# coex_secure register map
Vendor: Texas Instruments
Peripheral module from a debugger description file (folder CC35X1E).
Registers are 32-bit, access per field, reset 0x0 unless marked. A register's access mark holds for its fields unless they carry their own. Offsets are as the file gives them; lines under a group give offsets from that group; [hi:lo] are bit positions; {n}, {i} and the like mark numbered series; 'fields as' and 'values as' point back to an identical list; <NAME> marks a mode.

## coex_secure
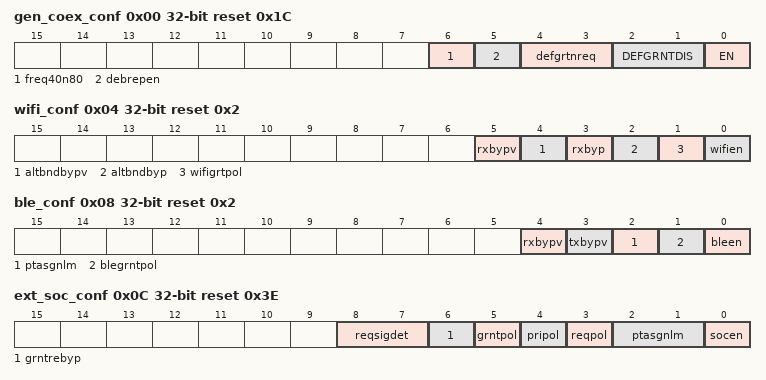
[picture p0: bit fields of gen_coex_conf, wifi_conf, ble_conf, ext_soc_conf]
0x00 gen_coex_conf reset 0x1C — General COEX Configurations. This register is a static configuration.
  [6] freq40n80 rw — This bit configuration is available to select the freq. at which COEX is operating. 1 --> 80 MHz; 0 --> 40 MHz.
  [5] debrepen rw — debug reporting enable: This bit configuration is available to enable or disable the debug reporting.0 --> No IRQ is generated; 1 --> Debug Mode enable. IRQ is generated whenever there is change in grant state.
  [4:3] defgrtnreq rw — def grant when no req: This bit configuration is available to select the entity which has the grant when there is no request from any entity.00 --> Wifi; 01 --> BLE, 10 --> SOC, 11 --> Wifi.
  [2:1] DEFGRNTDIS rw — def grant when coex disabled: This bit configuration is available to select the entity which has the grant when COEX is disabled. 00 --> Wifi; 01 --> BLE, 10 --> SOC, 11 --> invalid configuration.
  [0] EN rw — This bit configuration is available to enable or disable COEX. Enable --> 1; Disable --> 0.
0x04 wifi_conf reset 0x2 — Wifi Configuration. This register is available is to program Wifi related general configuration. This register is static configuration.
  [5] rxbypv rw — wifi rx only input bypass val: This bit configuration is available to bypass Wifi_RX_only value.
  [4] altbndbypv rw — wifi alt band input bypass val: This bit configuration is available to configure Wifi_alt_band value.
  [3] rxbyp rw — wifi rx only input bypass: This bit configuration is available to bypass Wifi RX only input. 1 --> Bypass wifi rx only input; 0 --> Do not bypass wifi rx only input.
  [2] altbndbyp rw — wifi alt band input bypass: This bit configuration is available to bypass Wifi alt band input. 1 --> Bypass wifi alt band input; 0 --> Do not bypass wifi alt band input.
  [1] wifigrtpol rw — This bit configuration is available to select Wifi Grant Polarity. 1 --> Default Polarity/Active Low; 0 --> Reverse Polarity/Active High.
  [0] wifien rw — This bit configuration is available to indicate if Wifi is enabled in the design or not. 0 --> Wifi disabled; 1 --> Wifi enabled..
0x08 ble_conf reset 0x2 — BLE Configuration. This register is available is to program BLE related general configuration. This register is static configuration.
  [4] rxbypv rw — ble rx bypass val: This bit configuration is available to configure BLE_RX value. This bit takes effect when mem_ble_pta_signalling_mode is set to 1.
  [3] txbypv rw — ble tx bypass val: This bit configuration is available to configure BLE_TX value. This bit takes effect when mem_ble_pta_signalling_mode is set to 1.
  [2] ptasgnlm rw — ble pta signalling mode: This bit configuration is available to select if BLE_TX and BLE_RX are to be bypassed. 1 --> Bypass BLE_TX and BLE_RX; 0 --> Do not bypass BLE_TX and BLE_RX input.
  [1] blegrntpol rw — This bit configuration is available to select BLE Grant Polarity. 1 --> Default Polarity/Active Low; 0 --> Reverse Polarity/Active High.
  [0] bleen rw — This bit configuration is available to indicate if BLE is enabled in the design or not. 0 --> BLE disabled; 1 --> BLE enabled..
0x0C ext_soc_conf reset 0x3E — SOC Configuration. This register is available is to program EXT SOC related general configuration. This register is a static configuration.
  [8:7] reqsigdet rw — This bit configuration is available to select detection mechanism for SOC request. 00 --> Rise edge detection (L -> H) ; 01 --> Fall edge detection (H -> L) ; 10 --> Level detection (active high) ; 11 -> level detection (active low).
  [6] grntrebyp rw — soc grant renew bypass: This bit configuration is available to bypass need to renew soc grant. 1 --> Bypass SOC grant renew; 0 --> SOC needs to renew grant.
  [5] grntpol rw — This bit configuration is available to select SOC Grant Polarity. 1 --> Default Polarity/Active Low; 0 --> Reverse Polarity/Active High.
  [4] pripol rw — This bit configuration is available to select Ext SOC Priority Polarity. 1 --> Default Polarity/Active High; 0 --> Reverse Polarity/Active Low.
  [3] reqpol rw — This bit configuration is available to select Ext SOC Request Polarity. 1 --> Default Polarity/Active High; 0 --> Reverse Polarity/Active Low.
  [2:1] ptasgnlm rw — soc pta signalling mode: This bit configuration is available to select the Ext SOC PTA signalling mode. 00 --> Reserved; 01 --> 1-wire, 10 --> 2-wires, 11 --> 3-wires.
  [0] socen rw — This bit configuration is available to indicate if SOC is enabled in the design or not. 0 --> SOC disabled; 1 --> SOC enabled..
0x10 ble_high_prio_rx — BLE High Priority Rx. This Priority register selected when BLE Priority is high and BLE_RX is asserted. This register value should not be changed when BLE request is asserted.
  [3:0] blehiprirx rw — Priority levels can be 1 to 15. 0 level indicates no request from BLE.
0x14 ble_low_prio_rx — BLE Low Priority Rx. This Priority register selected when BLE Priority is low and BLE_RX is asserted. This register value should not be changed when BLE request is asserted.
  [3:0] bleloprirx rw — Priority levels can be 1 to 15. 0 level indicates no request from BLE.
0x18 ble_high_prio_tx — BLE High Priority Tx. This Priority register selected when BLE Priority is high and BLE_TX is asserted. This register value should not be changed when BLE request is asserted.
  [3:0] blehipritx rw — Priority levels can be 1 to 15. 0 level indicates no request from BLE.
0x1C ble_low_prio_tx — BLE Low Priority Tx. This Priority register selected when BLE Priority is low and BLE_TX is asserted. This register value should not be changed when BLE request is asserted.
  [3:0] blelopritx rw — Priority levels can be 1 to 15. 0 level indicates no request from BLE.
0x20 soc_high_prio — SOC High Priority. This Priority register selected when SOC Priority is high. This register value should not be changed when SOC request is asserted.
  [3:0] sochipri rw — Priority levels can be 1 to 15. 0 level indicates no request from SOC.
0x24 soc_low_prio — SOC Low Priority. This Priority register selected when SOC Priority is low. This register value should not be changed when SOC request is asserted.
  [3:0] soclopri rw — Priority levels can be 1 to 15. 0 level indicates no request from SOC.
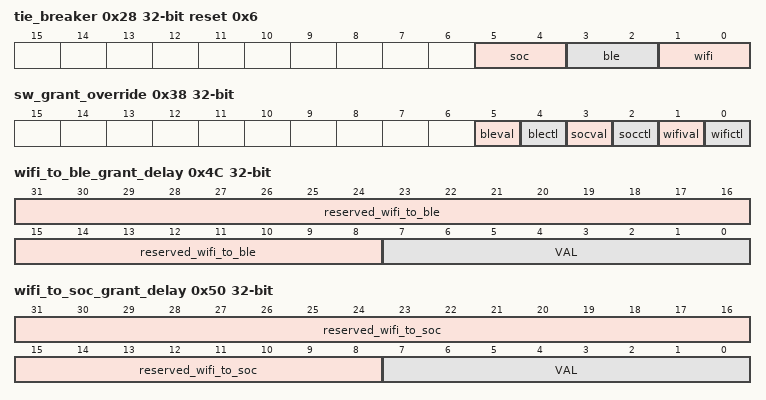
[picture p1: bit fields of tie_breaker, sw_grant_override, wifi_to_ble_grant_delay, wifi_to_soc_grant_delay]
0x28 tie_breaker reset 0x6 — Tie Breaker. This register is available is to program entity priority which comes into effect when there is a tie between contesting entities. This register is a static configuration. The values in all the three fields need to be unique.
  [5:4] soc rw — Priority value for SOC.
  [3:2] ble rw — Priority value for BLE.
  [1:0] wifi rw — Priority value for Wifi.
0x2C wifi_min_grant_time — WIFI MIN GRANT TIME: This register is available is to program wifi minimum grant time. This register is static configuration.
  [12:0] VAL rw — Wifi min grant time.
0x30 ble_min_grant_time — BLE MIN GRANT TIME: This register is available is to program ble minimum grant time. This register is static configuration.
  [12:0] VAL rw — BLE min grant time.
0x34 soc_min_grant_time — SOC MIN GRANT TIME: This register is available is to program soc minimum grant time. This register is static configuration.
  [12:0] VAL rw — SOC min grant time.
0x38 sw_grant_override — SW Grant Override. This register is available to override the grant via SW.
  [5] bleval rw — BLE grant override value.
  [4] blectl rw — BLE grant override control.
  [3] socval rw — soc grant override value.
  [2] socctl rw — soc grant override control.
  [1] wifival rw — wifi grant override value
  [0] wifictl rw — wifi grant override control.
0x3C ble_max_grant_time — BLE Max Grant Time. This register is available is to program ble maximum grant time. This register is static configuration.
  [13:0] VAL rw — BLE max grant time.
0x40 soc_max_grant_time — SOC Max Grant Time. This register is available is to program soc maximum grant time. This register is static configuration.
  [13:0] VAL rw — SOC max grant time.
0x44 ble_t2_time — BLE T2 Time. This register is available is to program ble T2 time. This register is static configuration.
  [5:0] VAL rw — BLE T2 time.
0x48 soc_t2_time — SOC T2 Time. This register is available is to program soc T2 time. This register is static configuration.
  [5:0] VAL rw — SOC T2 time.
0x4C wifi_to_ble_grant_delay — WIFI to BLE Grant Delay. This register is available is to program wifi to ble grant delay time. This register is static configuration.
  [31:8] reserved_wifi_to_ble ro
  [7:0] VAL rw — WIFI to BLE grant delay time.
0x50 wifi_to_soc_grant_delay — WIFI to SOC Grant Delay. This register is available is to program wifi to soc grant delay time. This register is static configuration.
  [31:8] reserved_wifi_to_soc ro
  [7:0] VAL rw — WIFI to SOC grant delay time.
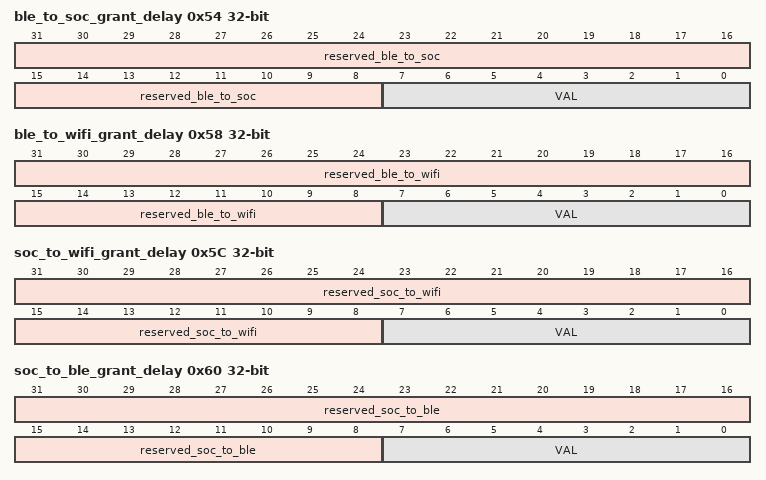
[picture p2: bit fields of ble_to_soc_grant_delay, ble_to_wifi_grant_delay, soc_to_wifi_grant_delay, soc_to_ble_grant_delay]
0x54 ble_to_soc_grant_delay — BLE to SOC Grant Delay. This register is available is to program ble to soc grant delay time. This register is static configuration.
  [31:8] reserved_ble_to_soc ro
  [7:0] VAL rw — BLE to SOC grant delay time.
0x58 ble_to_wifi_grant_delay — BLE to WIFI Grant Delay. This register is available is to program ble to wifi grant delay time. This register is static configuration.
  [31:8] reserved_ble_to_wifi ro
  [7:0] VAL rw — BLE to WIFI grant delay time.
0x5C soc_to_wifi_grant_delay — SOC to WIFI Grant Delay. This register is available is to program soc to wifi grant delay time. This register is static configuration.
  [31:8] reserved_soc_to_wifi ro
  [7:0] VAL rw — SOC to WIFI grant delay time.
0x60 soc_to_ble_grant_delay — SOC to BLE Grant Delay. This register is available is to program soc to ble grant delay time. This register is static configuration.
  [31:8] reserved_soc_to_ble ro
  [7:0] VAL rw — SOC to BLE grant delay time.
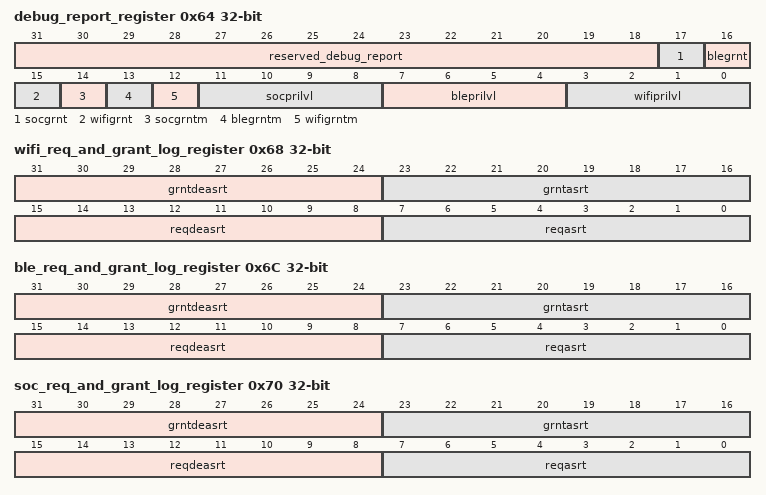
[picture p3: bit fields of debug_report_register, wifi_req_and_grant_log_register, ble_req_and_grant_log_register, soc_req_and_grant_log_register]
0x64 debug_report_register ro — Debug Report Register. This register captures state of COEX.
  [31:18] reserved_debug_report
  [17] socgrnt — This field of the register captures the soc_grant.
  [16] blegrnt — This field of the register captures the ble_grant.
  [15] wifigrnt — This field of the register captures the wifi_grant.
  [14] socgrntm — This field of the register captures the soc_grant_m.
  [13] blegrntm — This field of the register captures the ble_grant_m.
  [12] wifigrntm — This field of the register captures the wifi_grant_m.
  [11:8] socprilvl — This field of the register captures the soc_prio_lvl.
  [7:4] bleprilvl — This field of the register captures the ble_prio_lvl.
  [3:0] wifiprilvl — This field of the register captures the wifi_prio_lvl.
0x68 wifi_req_and_grant_log_register ro — WIFI Request and Grant Log Register. This register keeps a log of wifi request and grant.
  [31:24] grntdeasrt — This field of the register captures the number of times the wifi grant was deasserted since last reset.
  [23:16] grntasrt — This field of the register captures the number of times the wifi grant was asserted since last reset.
  [15:8] reqdeasrt — This field of the register captures the number of times the wifi request was dropped/deasserted since last reset.
  [7:0] reqasrt — This field of the register captures the number of times the wifi request was asserted since last reset.
0x6C ble_req_and_grant_log_register ro — BLE Request and Grant Log Register. This register keeps a log of ble request and grant.
  [31:24] grntdeasrt — This field of the register captures the number of times the ble grant was deasserted since last reset.
  [23:16] grntasrt — This field of the register captures the number of times the ble grant was asserted since last reset.
  [15:8] reqdeasrt — This field of the register captures the number of times the ble request was dropped/deasserted since last reset.
  [7:0] reqasrt — This field of the register captures the number of times the ble request was asserted since last reset.
0x70 soc_req_and_grant_log_register ro — SOC Request and Grant Log Register. This register keeps a log of soc request and grant.
  [31:24] grntdeasrt — This field of the register captures the number of times the soc grant was deasserted since last reset.
  [23:16] grntasrt — This field of the register captures the number of times the soc grant was asserted since last reset.
  [15:8] reqdeasrt — This field of the register captures the number of times the soc request was dropped/deasserted since last reset.
  [7:0] reqasrt — This field of the register captures the number of times the soc request was asserted since last reset.
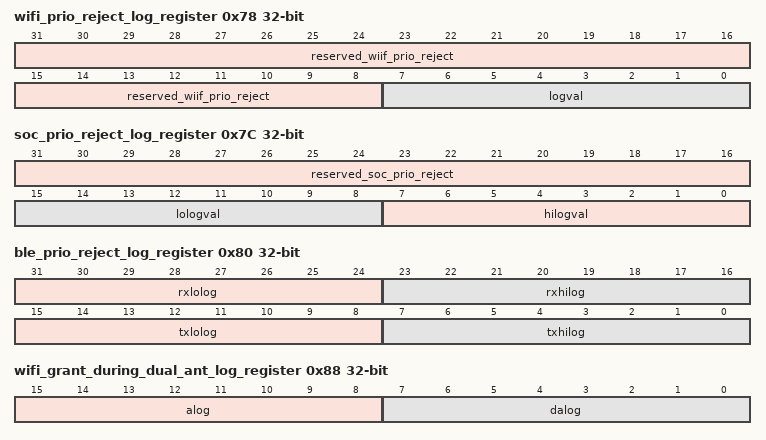
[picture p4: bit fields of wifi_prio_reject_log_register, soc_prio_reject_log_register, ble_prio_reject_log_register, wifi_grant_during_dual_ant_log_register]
0x78 wifi_prio_reject_log_register ro — WIFI Priority Reject Log Register. This register keeps a log of number of times wifi prio was rejected.
  [31:8] reserved_wiif_prio_reject — reserved.
  [7:0] logval — This field of the register captures the number of times the soc request was asserted since last reset.
0x7C soc_prio_reject_log_register ro — SOC Priority Reject Log Register. This register keeps a log of number of times soc prio was rejected.
  [31:16] reserved_soc_prio_reject — reserved.
  [15:8] lologval — This field of the register captures the number of times the soc low priority was rejected since last reset.
  [7:0] hilogval — This field of the register captures the number of times the soc high priority was rejected since last reset.
0x80 ble_prio_reject_log_register ro — BLE Priority Reject Log Register. This register keeps a log of number of times ble prio was rejected.
  [31:24] rxlolog — This field of the register captures the number of times the ble rx low priority was rejected since last reset.
  [23:16] rxhilog — This field of the register captures the number of times the ble rx high priority was rejected since last reset.
  [15:8] txlolog — This field of the register captures the number of times the ble tx low priority was rejected since last reset.
  [7:0] txhilog — This field of the register captures the number of times the ble tx high priority was rejected since last reset.
0x84 timestamp_register ro — Timestamp Register. This register captures the timestamp (from TSF counter) when the coex_irq was generated.
  [31:0] ts — This register captures the timestamp (from TSF counter) when the coex_irq was generated since last reset.
0x88 wifi_grant_during_dual_ant_log_register ro — WIFI Grant During Dual Antenna Log Register. This register keeps a log of number of times ble prio was rejected.
  [15:8] alog — This field of the register captures the number of times the wifi grant was deasserted during rx_only or alt_band mode since last reset.
  [7:0] dalog — This field of the register captures the number of times the wifi grant was deasserted during rx_only or alt_band mode since last reset.
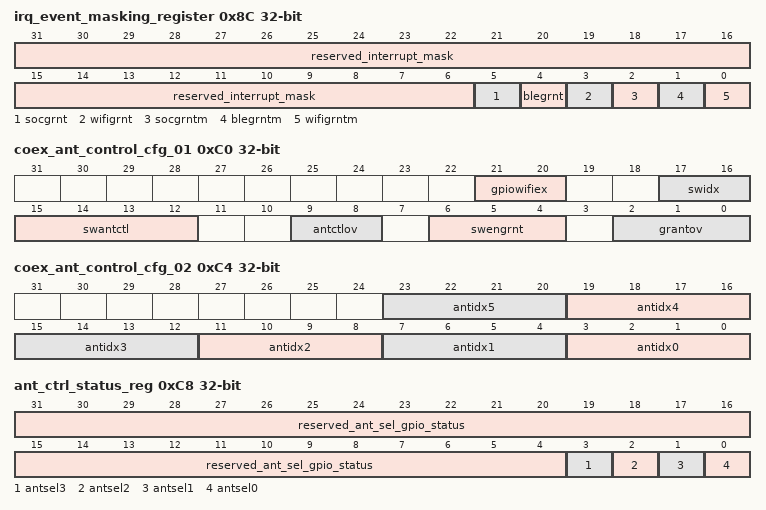
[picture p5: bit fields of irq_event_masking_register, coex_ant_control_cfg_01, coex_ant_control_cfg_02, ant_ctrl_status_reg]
0x8C irq_event_masking_register — IRQ Event Masking. This register can be configured to mask the IRQ event.
  [31:6] reserved_interrupt_mask ro — reserved
  [5] socgrnt rw — This field of the register is used to mask the interrupt generation caused due to changes in soc_grant. 1--> mask the IRQ; 0 --> Unmask the IRQ
  [4] blegrnt rw — This field of the register is used to mask the interrupt generation caused due to changes in ble_grant. 1--> mask the IRQ; 0 --> Unmask the IRQ
  [3] wifigrnt rw — This field of the register is used to mask the interrupt generation caused due to changes in wifi_grant. 1--> mask the IRQ; 0 --> Unmask the IRQ
  [2] socgrntm rw — This field of the register is used to mask the interrupt generation caused due to changes in soc_grant_m. 1--> mask the IRQ; 0 --> Unmask the IRQ
  [1] blegrntm rw — This field of the register is used to mask the interrupt generation caused due to changes in ble_grant_m. 1--> mask the IRQ; 0 --> Unmask the IRQ
  [0] wifigrntm rw — This field of the register is used to mask the interrupt generation caused due to changes in wifi_grant_m. 1--> mask the IRQ; 0 --> Unmask the IRQ
0xC0 coex_ant_control_cfg_01 — Antenna Control Configuration 1.
  [21:20] gpiowifiex rw — FW padding for Wifi Core inputs for output mux
  [17:16] swidx rw — Bit 0 - SW index value Bit 1 - SW index override
  [15:12] swantctl rw — SW Enable register <4>
  [9:8] antctlov rw — antenna control Mux override <2>
  [6:4] swengrnt rw — 0- External mask mode 1- BLE Only 2- WiFi Only
  [2:0] grantov rw — 0- External enable 1- BLE only enable 2- WiFi only enable
0xC4 coex_ant_control_cfg_02 — Antenna Control Configuration 2.
  [4n+3:4n] antidx{n} rw (n=0..5) — index {n} - GPIO ANT Polarity 6x4. Mem is statically set on init
0xC8 ant_ctrl_status_reg ro — Antenna Control Status.
  [31:4] reserved_ant_sel_gpio_status — reserved.
  [3] antsel3 — Captures the ant_sel_3 bit.
  [2] antsel2 — Captures the ant_sel_2 bit .
  [1] antsel1 — Captures the ant_sel_1 bit.
  [0] antsel0 — Captures the ant_sel_0 bit.
